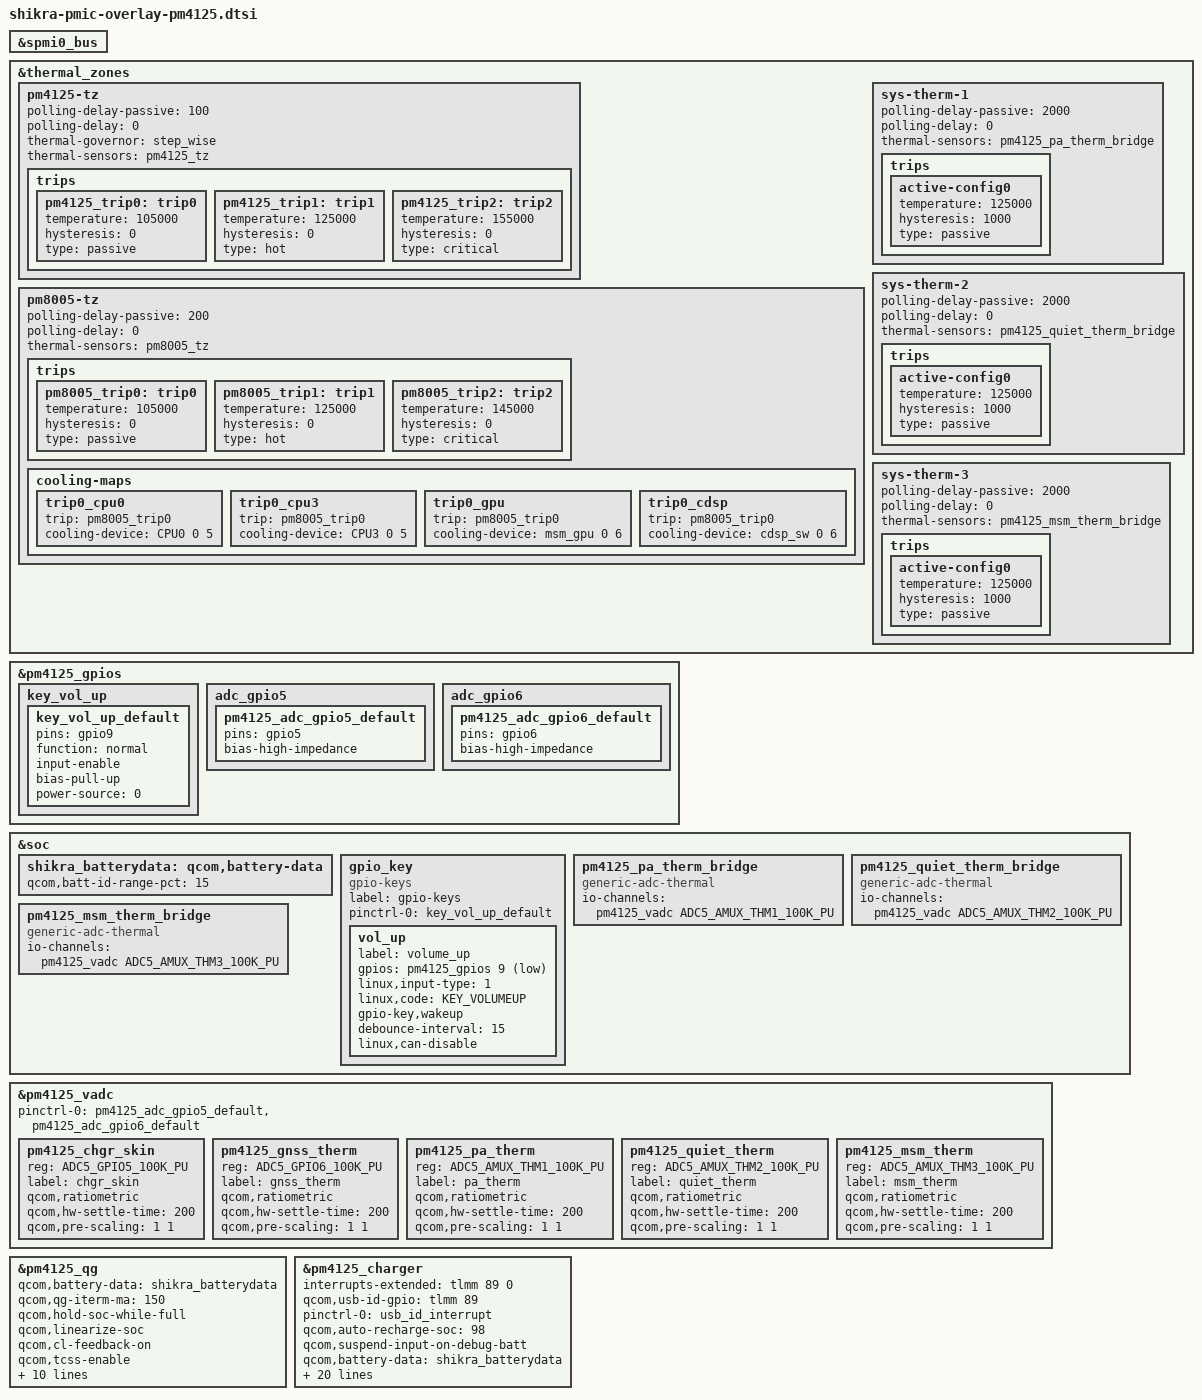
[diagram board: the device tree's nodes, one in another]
// SPDX-License-Identifier: BSD-3-Clause
/*
 * Copyright (c) Qualcomm Technologies, Inc. and/or its subsidiaries.
 */

#include <dt-bindings/gpio/gpio.h>
#include <dt-bindings/input/input.h>
#include <dt-bindings/iio/qcom,spmi-vadc.h>
#include <dt-bindings/iio/qti_power_supply_iio.h>

&spmi0_bus {
	#include "pm4125.dtsi"
	#include "pm8005.dtsi"
};

&thermal_zones {
	pm4125-tz {
		polling-delay-passive = <100>;
		polling-delay = <0>;
		thermal-governor = "step_wise";
		thermal-sensors = <&pm4125_tz>;

		trips {
			pm4125_trip0: trip0 {
				temperature = <105000>;
				hysteresis = <0>;
				type = "passive";
			};

			pm4125_trip1: trip1 {
				temperature = <125000>;
				hysteresis = <0>;
				type = "hot";
			};

			pm4125_trip2: trip2 {
				temperature = <155000>;
				hysteresis = <0>;
				type = "critical";
			};
		};
	};

	pm8005-tz {
		polling-delay-passive = <200>;
		polling-delay = <0>;
		thermal-sensors = <&pm8005_tz>;

		trips {
			pm8005_trip0: trip0 {
				temperature = <105000>;
				hysteresis = <0>;
				type = "passive";
			};

			pm8005_trip1: trip1 {
				temperature = <125000>;
				hysteresis = <0>;
				type = "hot";
			};

			pm8005_trip2: trip2 {
				temperature = <145000>;
				hysteresis = <0>;
				type = "critical";
			};
		};

		cooling-maps {
			trip0_cpu0 {
				trip = <&pm8005_trip0>;
				cooling-device = <&CPU0 0 5>;
			};

			trip0_cpu3 {
				trip = <&pm8005_trip0>;
				cooling-device = <&CPU3 0 5>;
			};

			trip0_gpu {
				trip = <&pm8005_trip0>;
				cooling-device = <&msm_gpu 0 6>;
			};

			trip0_cdsp {
				trip = <&pm8005_trip0>;
				cooling-device = <&cdsp_sw 0 6>;
			};
		};
	};

	sys-therm-1 {
		polling-delay-passive = <2000>;
		polling-delay = <0>;
		thermal-sensors = <&pm4125_pa_therm_bridge>;

		trips {
			active-config0 {
				temperature = <125000>;
				hysteresis = <1000>;
				type = "passive";
			};
		};
	};

	sys-therm-2 {
		polling-delay-passive = <2000>;
		polling-delay = <0>;
		thermal-sensors = <&pm4125_quiet_therm_bridge>;

		trips {
			active-config0 {
				temperature = <125000>;
				hysteresis = <1000>;
				type = "passive";
			};
		};
	};

	sys-therm-3 {
		polling-delay-passive = <2000>;
		polling-delay = <0>;
		thermal-sensors = <&pm4125_msm_therm_bridge>;

		trips {
			active-config0 {
				temperature = <125000>;
				hysteresis = <1000>;
				type = "passive";
			};
		};
	};
};

&pm4125_gpios {
	key_vol_up {
		key_vol_up_default: key_vol_up_default {
			pins = "gpio9";
			function = "normal";
			input-enable;
			bias-pull-up;
			power-source = <0>;
		};
	};

	adc_gpio5 {
		pm4125_adc_gpio5_default: pm4125_adc_gpio5_default {
			pins = "gpio5";
			bias-high-impedance;
		};
	};

	adc_gpio6 {
		pm4125_adc_gpio6_default: pm4125_adc_gpio6_default {
			pins = "gpio6";
			bias-high-impedance;
		};
	};
};

&soc {

	shikra_batterydata: qcom,battery-data {
		qcom,batt-id-range-pct = <15>;
		#include "qg-batterydata-hawi0000903-4353mAh.dtsi"
	};

	gpio_key {
		compatible = "gpio-keys";
		label = "gpio-keys";
		pinctrl-names = "default";
		pinctrl-0 = <&key_vol_up_default>;

		vol_up {
			label = "volume_up";
			gpios = <&pm4125_gpios 9 GPIO_ACTIVE_LOW>;
			linux,input-type = <1>;
			linux,code = <KEY_VOLUMEUP>;
			gpio-key,wakeup;
			debounce-interval = <15>;
			linux,can-disable;
		};
	};

	pm4125_pa_therm_bridge: pm4125_pa_therm_bridge {
		compatible = "generic-adc-thermal";
		io-channels = <&pm4125_vadc ADC5_AMUX_THM1_100K_PU>;
		io-channel-names = "sensor-channel";
		#thermal-sensor-cells = <0>; /* It becomes the sensor provider */
	};

	pm4125_quiet_therm_bridge: pm4125_quiet_therm_bridge {
		compatible = "generic-adc-thermal";
		io-channels = <&pm4125_vadc ADC5_AMUX_THM2_100K_PU>;
		io-channel-names = "sensor-channel";
		#thermal-sensor-cells = <0>;
	};

	pm4125_msm_therm_bridge: pm4125_msm_therm_bridge {
		compatible = "generic-adc-thermal";
		io-channels = <&pm4125_vadc ADC5_AMUX_THM3_100K_PU>;
		io-channel-names = "sensor-channel";
		#thermal-sensor-cells = <0>;
	};
};

&pm4125_vadc {
	pinctrl-0 = <&pm4125_adc_gpio5_default>, <&pm4125_adc_gpio6_default>;
	pinctrl-names = "default";

	pm4125_chgr_skin {
		reg = <ADC5_GPIO5_100K_PU>;
		label = "chgr_skin";
		qcom,ratiometric;
		qcom,hw-settle-time = <200>;
		qcom,pre-scaling = <1 1>;
	};

	pm4125_gnss_therm {
		reg = <ADC5_GPIO6_100K_PU>;
		label = "gnss_therm";
		qcom,ratiometric;
		qcom,hw-settle-time = <200>;
		qcom,pre-scaling = <1 1>;
	};

	pm4125_pa_therm {
		reg = <ADC5_AMUX_THM1_100K_PU>;
		label = "pa_therm";
		qcom,ratiometric;
		qcom,hw-settle-time = <200>;
		qcom,pre-scaling = <1 1>;
	};

	pm4125_quiet_therm {
		reg = <ADC5_AMUX_THM2_100K_PU>;
		label = "quiet_therm";
		qcom,ratiometric;
		qcom,hw-settle-time = <200>;
		qcom,pre-scaling = <1 1>;
	};

	pm4125_msm_therm {
		reg = <ADC5_AMUX_THM3_100K_PU>;
		label = "msm_therm";
		qcom,ratiometric;
		qcom,hw-settle-time = <200>;
		qcom,pre-scaling = <1 1>;
	};
};

&pm4125_qg {
	qcom,battery-data = <&shikra_batterydata>;
	qcom,qg-iterm-ma = <150>;
	qcom,hold-soc-while-full;
	qcom,linearize-soc;
	qcom,cl-feedback-on;
	qcom,tcss-enable;
	qcom,fvss-enable;
	qcom,fvss-vbatt-mv = <3500>;
	qcom,bass-enable;
	#io-channel-cells = <1>;

	io-channels = <&pm4125_vadc ADC5_BAT_THERM_100K_PU>,
		      <&pm4125_vadc ADC5_BAT_ID_100K_PU>,
		      <&pm4125_charger PSY_IIO_INPUT_CURRENT_LIMITED>,
		      <&pm4125_charger PSY_IIO_RECHARGE_SOC>,
		      <&pm4125_charger PSY_IIO_FORCE_RECHARGE>,
		      <&pm4125_charger PSY_IIO_CHARGE_DONE>;
	io-channel-names = "batt-therm",
			   "batt-id",
			   "input_current_limited",
			   "recharge_soc",
			   "force_recharge",
			   "charge_done";
};

&pm4125_charger {
	interrupts-extended = <&tlmm 89 0>;
	interrupt-names = "usb_id_irq";
	qcom,usb-id-gpio = <&tlmm 89 0>;

	pinctrl-names = "default";
	pinctrl-0 = <&usb_id_interrupt>;

	qcom,auto-recharge-soc = <98>;
	qcom,suspend-input-on-debug-batt;
	qcom,battery-data = <&shikra_batterydata>;
	#io-channel-cells = <1>;

	io-channels = <&pm4125_vadc ADC5_USB_IN_V_16>,
		      <&pm4125_vadc ADC5_CHG_TEMP>,
		      <&pm4125_qg PSY_IIO_RESISTANCE_ID>,
		      <&pm4125_qg PSY_IIO_VOLTAGE_NOW>,
		      <&pm4125_qg PSY_IIO_TEMP>,
		      <&pm4125_qg PSY_IIO_CAPACITY>,
		      <&pm4125_qg PSY_IIO_VOLTAGE_OCV>,
		      <&pm4125_qg PSY_IIO_VOLTAGE_AVG>,
		      <&pm4125_qg PSY_IIO_DEBUG_BATTERY>,
		      <&pm4125_qg PSY_IIO_REAL_CAPACITY>,
		      <&pm4125_qg PSY_IIO_CC_SOC>,
		      <&pm4125_qg PSY_IIO_CURRENT_NOW>,
		      <&pm4125_qg PSY_IIO_VOLTAGE_MAX>,
		      <&pm4125_qg PSY_IIO_CHARGE_FULL>,
		      <&pm4125_qg PSY_IIO_CHARGE_COUNTER>,
		      <&pm4125_qg PSY_IIO_CYCLE_COUNT>,
		      <&pm4125_qg PSY_IIO_CHARGE_FULL_DESIGN>,
		      <&pm4125_qg PSY_IIO_TIME_TO_FULL_NOW>;
	io-channel-names = "usb_in_voltage",
			   "chg_temp",
			   "resistance_id",
			   "voltage_now",
			   "temp",
			   "capacity",
			   "voltage_ocv",
			   "voltage_avg",
			   "debug_battery",
			   "real_capacity",
			   "cc_soc",
			   "current_now",
			   "voltage_max",
			   "charge_full",
			   "charge_counter",
			   "cycle_count",
			   "charge_full_design",
			   "time_to_full_now";
	qcom,thermal-mitigation = <2000000 1500000 1000000 500000>;
};
